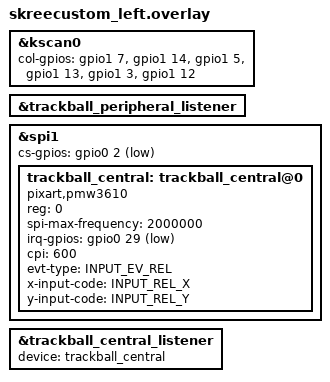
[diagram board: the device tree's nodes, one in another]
#include "skreecustom.dtsi"

&kscan0 {
    col-gpios           // Col1-7 1.07 1.14 1.05 1.13 1.03 1.12 0.16 
        = <&gpio1 7 GPIO_ACTIVE_HIGH> 
        , <&gpio1 14 GPIO_ACTIVE_HIGH>
        , <&gpio1 5 GPIO_ACTIVE_HIGH>
        , <&gpio1 13 GPIO_ACTIVE_HIGH> 
        , <&gpio1 3 GPIO_ACTIVE_HIGH> 
        , <&gpio1 12 GPIO_ACTIVE_HIGH> 
//      , <&gpio0 16 GPIO_ACTIVE_HIGH> 
        ;
};

&trackball_peripheral_listener {
    status = "okay";
};

#include <zephyr/dt-bindings/input/input-event-codes.h>
&spi1 {
    cs-gpios = <&gpio0 2 GPIO_ACTIVE_LOW>;

    trackball_central: trackball_central@0 {
        status = "okay";
        compatible = "pixart,pmw3610";
        reg = <0>;
        spi-max-frequency = <2000000>;
        irq-gpios = <&gpio0 29 (GPIO_ACTIVE_LOW | GPIO_PULL_UP)>;
        cpi = <600>;
        evt-type = <INPUT_EV_REL>;
        x-input-code = <INPUT_REL_X>;
        y-input-code = <INPUT_REL_Y>;
    };
};

// Overrides for the input listener node
&trackball_central_listener {
    status = "okay";
    device = <&trackball_central>;
};
